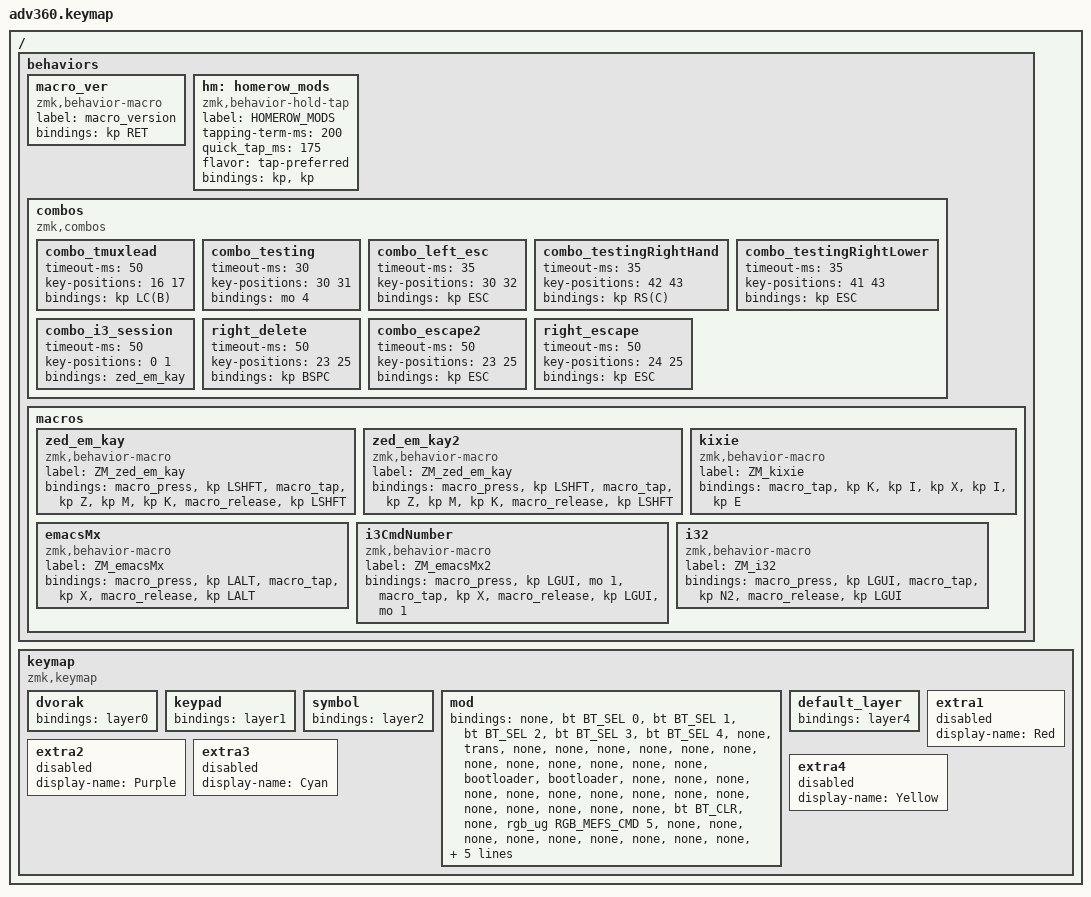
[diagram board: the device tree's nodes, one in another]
#include <behaviors.dtsi>
#include <dt-bindings/zmk/keys.h>
#include <dt-bindings/zmk/bt.h>
#include <dt-bindings/zmk/rgb.h>
#include <dt-bindings/zmk/stp.h>
#include <dt-bindings/zmk/backlight.h>
#include <dt-bindings/zmk/pointing.h>

#include "defs.dtsi"
#include "layer0.dtsi"
#include "layer1.dtsi"
#include "layer2.dtsi"
#include "layer4.dtsi"

/ {
    behaviors {
      #include "macros.dtsi"
      #include "i3_macros.dtsi"
      #include "version.dtsi"
      #ifndef VERSION_MACRO
      macro_ver: macro_ver {
        compatible = "zmk,behavior-macro";
        label = "macro_version";
        #binding-cells = <0>;
        bindings = <&kp RET>;
      };
      #endif

      hm: homerow_mods {
          compatible = "zmk,behavior-hold-tap";
          label = "HOMEROW_MODS";
          #binding-cells = <2>;
          tapping-term-ms = <200>;
          quick_tap_ms = <175>;
          flavor = "tap-preferred";
          bindings = <&kp>, <&kp>;
      };

      combos {
          compatible = "zmk,combos";
          combo_tmuxlead {
              timeout-ms = <50>;
              key-positions = <16 17>;
              bindings = <&kp LC(B)>;
          };
          combo_testing {
              timeout-ms = <30>;
              key-positions = <30 31>; // Left hand middle row, ring+middle(o+e)
              bindings = <&mo 4>;
          };
          combo_left_esc {
              timeout-ms = <35>;
              key-positions = <30 32>; // Left hand middle row, ring+pointer(o+u)
              bindings = <&kp ESC>;
          };
          combo_testingRightHand {
              timeout-ms = <35>;
              key-positions = <42 43>; // Right hand middle row, middle+ring(t+n)
              bindings = <&kp RS(C)>;
          };
          combo_testingRightLower {
              timeout-ms = <35>;
              key-positions = <41 43>; // Right hand middle row, pointer+middle(h+n)
              bindings = <&kp ESC>;
          };
          combo_i3_session { // this is a COMBO using a MACRO
              timeout-ms = <50>;
              key-positions = <0 1>;
              bindings = <&zed_em_kay>;
          };
          // combo_sanity {
          //     timeout-ms = <50>;
          //     key-positions = <0 1>;
          //     bindings = <&kp LS(A)>;
          // };
          right_delete {
              timeout-ms = <50>;
              key-positions = <23 25>; // Right hand upper row, pointer+ring(g+r)
              bindings = <&kp BSPC>;
          };
          combo_escape2 {
              timeout-ms = <50>;
              key-positions = <23 25>; // Right hand upper row, pointer+ring(g+r)
              bindings = <&kp ESC>;
          };
          right_escape {
              timeout-ms = <50>;
              key-positions = <24 25>; // Right hand upper row, middle+ring(c+r) (Right hand equivalent of tmux leader)
              bindings = <&kp ESC>;
          };
          // letsseeifthisworks {
          //     timeout-ms = <50>;
          //     key-positions = <TEST>; // Right hand upper row, most left two keys (would press with ring+pinky)
          //     bindings = <&kp LGUI &mo 1>;
          // };
          // letsseeifthisworks2 {
          //     timeout-ms = <50>;
          //     key-positions = <44 45>; // Left hand lower row, ring + middle (q+j)
          //     bindings = <&kp LGUI &mo 1>;
          // };
      };

      macros {
          zed_em_kay: zed_em_kay {
              label = "ZM_zed_em_kay";
              compatible = "zmk,behavior-macro";
              #binding-cells = <0>;
              bindings
                  = <&macro_press &kp LSHFT>
                  , <&macro_tap &kp Z &kp M &kp K>
                  , <&macro_release &kp LSHFT>
                  ;
          };
          zed_em_kay2: zed_em_kay2 {
              label = "ZM_zed_em_kay";
              compatible = "zmk,behavior-macro";
              #binding-cells = <0>;
              bindings
                  = <&macro_press &kp LSHFT>
                  , <&macro_tap &kp Z &kp M &kp K>
                  , <&macro_release &kp LSHFT>
                  ;
          };
          kixie: kixie {
              label = "ZM_kixie";
              compatible = "zmk,behavior-macro";
              #binding-cells = <0>;
              bindings
                  = <&macro_tap &kp K &kp I &kp X &kp I &kp E>
                  ;
          };
          emacsMx: emacsMx {
              label = "ZM_emacsMx";
              compatible = "zmk,behavior-macro";
              #binding-cells = <0>;
              bindings
                  = <&macro_press &kp LALT>
                  , <&macro_tap &kp X>
                  , <&macro_release &kp LALT>
                  ;
          };
          i3CmdNumber: i3CmdNumber {
              label = "ZM_emacsMx2";
              compatible = "zmk,behavior-macro";
              #binding-cells = <0>;
              bindings
                  = <&macro_press &kp LGUI &mo 1>
                  , <&macro_tap &kp X>
                  , <&macro_release &kp LGUI &mo 1>
                  ;
          };
          i32: i32 {
              label = "ZM_i32";
              compatible = "zmk,behavior-macro";
              #binding-cells = <0>;
              bindings
                  = <&macro_press &kp LGUI>
                  , <&macro_tap &kp N2>
                  , <&macro_release &kp LGUI>
                  ;
          };
      };
    };

  keymap {
    compatible = "zmk,keymap";

    dvorak {
      bindings = < layer0 >;
    };
    keypad {
      bindings = < layer1 >;
    };
    symbol {
      bindings = < layer2 >;
    };
    mod {
      bindings = <
        &none &bt BT_SEL 0 &bt BT_SEL 1 &bt BT_SEL 2 &bt BT_SEL 3 &bt BT_SEL 4 &none                                                                     &trans                 &none        &none        &none        &none &none &none
        &none &none        &none        &none        &none        &none        &bootloader                                                               &bootloader            &none        &none        &none        &none &none &none
        &none &none        &none        &none        &none        &none        &none                   &none &none &bt BT_CLR &none                      &rgb_ug RGB_MEFS_CMD 5 &none        &none        &none        &none &none &none
        &none &none        &none        &none        &macro_ver   &none                                      &none &none                                                        &none        &none        &none        &none &none &none
        &none &none        &none        &none        &none                                       &none &none &none &none      &bl BL_TOG &rgb_ug RGB_TOG                                     &bl BL_INC   &bl BL_DEC   &none &none &none
      >;
    };
    default_layer {
      bindings = < layer4 >;
    };
    extra1 { 
      display-name = "Red";    
      status = "reserved";
    };

    extra2 { 
      display-name = "Purple";    
      status = "reserved";
    };

    extra3 { 
      display-name = "Cyan";    
      status = "reserved";
    };

    extra4 { 
      display-name = "Yellow";    
      status = "reserved";
    };
  };
};
